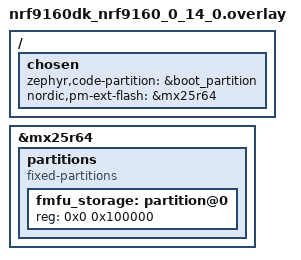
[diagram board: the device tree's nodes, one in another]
/*
 * Copyright (c) 2023 Nordic Semiconductor ASA
 *
 * SPDX-License-Identifier: LicenseRef-Nordic-5-Clause
 */

/ {
	chosen {
		zephyr,code-partition = &boot_partition;
		nordic,pm-ext-flash = &mx25r64;
	};
};

/* External flash device is disabled by default */
&mx25r64 {
	status = "okay";

	partitions {
		compatible = "fixed-partitions";
		#address-cells = <1>;
		#size-cells = <1>;

		fmfu_storage: partition@0 {
			reg = <0x0 0x100000>; /* 1 MB */
		};
	};
};

#include <common/nordic/nrf91_partitions_mcuboot.dtsi>
